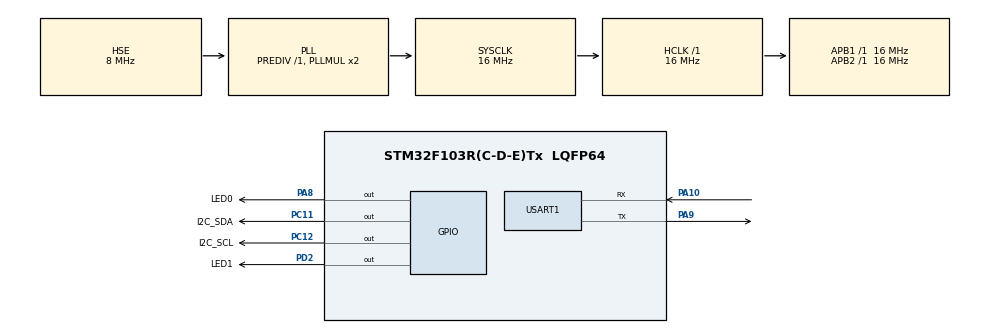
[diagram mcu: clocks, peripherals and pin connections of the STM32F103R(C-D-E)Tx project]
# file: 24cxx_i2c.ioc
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Mcu.Family=STM32F1
Mcu.Name=STM32F103R(C-D-E)Tx
Mcu.Package=LQFP64
NVIC.PriorityGroup=NVIC_PRIORITYGROUP_4
NVIC.USART1_IRQn=true\:2\:0\:true\:false\:true\:true\:true\:true
PA10.Mode=Asynchronous
PA10.Signal=USART1_RX
PA13.Mode=Serial_Wire
PA13.Signal=SYS_JTMS-SWDIO
PA14.Mode=Serial_Wire
PA14.Signal=SYS_JTCK-SWCLK
PA8.GPIO_Label=LED0
PA8.Signal=GPIO_Output
PA9.Mode=Asynchronous
PA9.Signal=USART1_TX
PC11.GPIO_Label=I2C_SDA
PC11.GPIO_ModeDefaultOutputPP=GPIO_MODE_OUTPUT_OD
PC11.GPIO_PuPd=GPIO_NOPULL
PC11.GPIO_Speed=GPIO_SPEED_FREQ_HIGH
PC11.Signal=GPIO_Output
PC12.GPIO_Label=I2C_SCL
PC12.GPIO_ModeDefaultOutputPP=GPIO_MODE_OUTPUT_PP
PC12.GPIO_PuPd=GPIO_NOPULL
PC12.GPIO_Speed=GPIO_SPEED_FREQ_HIGH
PC12.Signal=GPIO_Output
PD0-OSC_IN.Mode=HSE-External-Oscillator
PD0-OSC_IN.Signal=RCC_OSC_IN
PD1-OSC_OUT.Mode=HSE-External-Oscillator
PD1-OSC_OUT.Signal=RCC_OSC_OUT
PD2.GPIO_Label=LED1
PD2.Signal=GPIO_Output
ProjectManager.HeapSize=0x200
ProjectManager.StackSize=0x400
ProjectManager.TargetToolchain=CMake
RCC.AHBFreq_Value=16000000
RCC.APB1Freq_Value=16000000
RCC.APB1TimFreq_Value=16000000
RCC.APB2Freq_Value=16000000
RCC.APB2TimFreq_Value=16000000
RCC.HCLKFreq_Value=16000000
RCC.PLLSourceVirtual=RCC_PLLSOURCE_HSE
RCC.SYSCLKFreq_VALUE=16000000
RCC.SYSCLKSource=RCC_SYSCLKSOURCE_PLLCLK
RCC.USBFreq_Value=16000000
USART1.VirtualMode=VM_ASYNC
board=custom

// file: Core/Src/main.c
/* USER CODE BEGIN Header */
/**
 ******************************************************************************
 * @file           : main.c
 * @brief          : Main program body
 ******************************************************************************
 * @attention
 *
 * Copyright (c) 2024 STMicroelectronics.
 * All rights reserved.
 *
 * This software is licensed under terms that can be found in the LICENSE file
 * in the root directory of this software component.
 * If no LICENSE file comes with this software, it is provided AS-IS.
 *
 ******************************************************************************
 */
/* USER CODE END Header */
#include "main.h"

#include <errno.h>
#include <sys/unistd.h>

#include "24cxx.h"
#include "gpio.h"
#include "lcd.h"
#include "usart.h"

/* USER CODE BEGIN PV */
extern USARTRecvBuffer USART1Buffer;
extern uint8_t data_buf[BUF_SIZE];
/* USER CODE END PV */

void SystemClock_Config(void);

/* USER CODE BEGIN 0 */
int _write(int file, char *data, int len) {
  if ((file != STDOUT_FILENO) && (file != STDERR_FILENO)) {
    errno = EBADF;
    return -1;
  }

  // arbitrary timeout 1000
  HAL_StatusTypeDef status = HAL_UART_Transmit(&huart1, (uint8_t *)data, len, 0xFFFF);

  // return # of bytes written - as best we can tell
  return (status == HAL_OK ? len : 0);
}
/* USER CODE END 0 */

int main(void) {

  /* MCU Configuration--------------------------------------------------------*/

  /* Reset of all peripherals, Initializes the Flash interface and the Systick. */
  HAL_Init();

  /* Configure the system clock */
  SystemClock_Config();

  /* Initialize all configured peripherals */
  MX_GPIO_Init();
  MX_USART1_UART_Init();
  /* USER CODE BEGIN 2 */
  LCD_Init();
  AT24CXX_Init();
  HAL_UART_Receive_IT(&huart1, (uint8_t *)USART1Buffer.curBuffer, 1);
  LCD_ShowString(40, 120, 200, 16, 16, "24C02 Ready!");
  /* USER CODE END 2 */

  /* Infinite loop */
  /* USER CODE BEGIN WHILE */
  while (AT24CXX_Check()) {
  }
  while (1) {
    /* USER CODE END WHILE */
    if (1) {
      LCD_ShowString(40, 140, 200, 16, 16, data_buf);
    }
  }
}

void SystemClock_Config(void) {
  RCC_OscInitTypeDef RCC_OscInitStruct = {0};
  RCC_ClkInitTypeDef RCC_ClkInitStruct = {0};

  /** Initializes the RCC Oscillators according to the specified parameters
   * in the RCC_OscInitTypeDef structure.
   */
  RCC_OscInitStruct.OscillatorType = RCC_OSCILLATORTYPE_HSE;
  RCC_OscInitStruct.HSEState = RCC_HSE_ON;
  RCC_OscInitStruct.HSEPredivValue = RCC_HSE_PREDIV_DIV1;
  RCC_OscInitStruct.HSIState = RCC_HSI_ON;
  RCC_OscInitStruct.PLL.PLLState = RCC_PLL_ON;
  RCC_OscInitStruct.PLL.PLLSource = RCC_PLLSOURCE_HSE;
  RCC_OscInitStruct.PLL.PLLMUL = RCC_PLL_MUL2;
  if (HAL_RCC_OscConfig(&RCC_OscInitStruct) != HAL_OK) {
    Error_Handler();
  }

  /** Initializes the CPU, AHB and APB buses clocks
   */
  RCC_ClkInitStruct.ClockType = RCC_CLOCKTYPE_HCLK | RCC_CLOCKTYPE_SYSCLK | RCC_CLOCKTYPE_PCLK1 | RCC_CLOCKTYPE_PCLK2;
  RCC_ClkInitStruct.SYSCLKSource = RCC_SYSCLKSOURCE_PLLCLK;
  RCC_ClkInitStruct.AHBCLKDivider = RCC_SYSCLK_DIV1;
  RCC_ClkInitStruct.APB1CLKDivider = RCC_HCLK_DIV1;
  RCC_ClkInitStruct.APB2CLKDivider = RCC_HCLK_DIV1;

  if (HAL_RCC_ClockConfig(&RCC_ClkInitStruct, FLASH_LATENCY_0) != HAL_OK) {
    Error_Handler();
  }
}

void Error_Handler(void) {
  __disable_irq();
  while (1) {
  }
}
